VERSION ""

NS_ :

BS_:

BU_: PE3_ECU FR_Upright FL_Upright RR_Upright RL_Upright Data_MCU PWR_MCU Front_Sensor_Board Rear_Sensor_Board CG_Sensor_Board Telemetry Dash
VAL_TABLE_ Telem_OK_Value 1 "ERROR" 0 "OK" ;

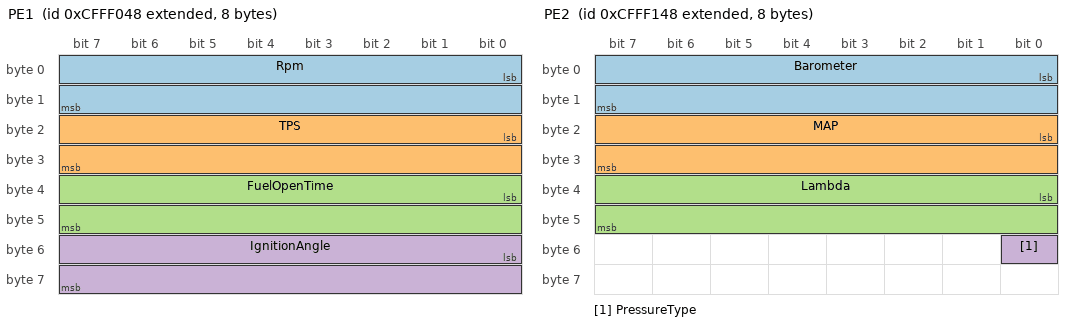
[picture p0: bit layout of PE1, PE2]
BO_ 2365583432 PE1: 8 PE3_ECU
 SG_ Rpm : 0|16@1+ (1,0) [0|30000] "rpm"  Telemetry
 SG_ TPS : 16|16@1- (0.1,0) [0|100] "%"  Telemetry
 SG_ FuelOpenTime : 32|16@1- (0.1,0) [0|30] "volts"  Telemetry
 SG_ IgnitionAngle : 48|16@1- (0.1,0) [-20|100] "deg"  Telemetry

BO_ 2365583688 PE2: 8 PE3_ECU
 SG_ Barometer : 0|16@1- (0.01,0) [0|300] "psi"  Telemetry
 SG_ MAP : 16|16@1- (0.01,0) [0|300] "psi"  Telemetry
 SG_ Lambda : 32|16@1- (0.01,0) [0|10] "lambda"  Telemetry
 SG_ PressureType : 48|1@1+ (1,0) [0|1] "0-psi,1-kPa"  Telemetry

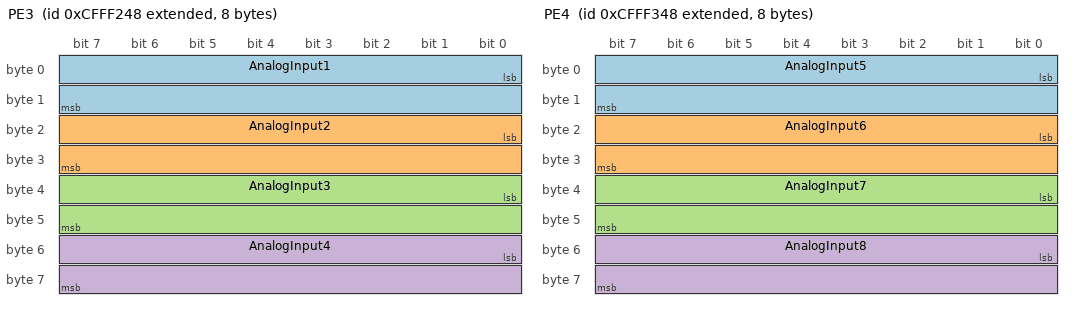
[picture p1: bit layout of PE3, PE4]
BO_ 2365583944 PE3: 8 PE3_ECU
 SG_ AnalogInput1 : 0|16@1- (0.001,0) [0|5] "volts"  Telemetry
 SG_ AnalogInput2 : 16|16@1- (0.001,0) [0|5] "volts"  Telemetry
 SG_ AnalogInput3 : 32|16@1- (0.001,0) [0|5] "volts"  Telemetry
 SG_ AnalogInput4 : 48|16@1- (0.001,0) [0|5] "volts"  Telemetry

BO_ 2365584200 PE4: 8 PE3_ECU
 SG_ AnalogInput5 : 0|16@1- (0.001,0) [0|5] "volts"  Telemetry
 SG_ AnalogInput6 : 16|16@1- (0.001,0) [0|5] "volts"  Telemetry
 SG_ AnalogInput7 : 32|16@1- (0.001,0) [0|5] "volts"  Telemetry
 SG_ AnalogInput8 : 48|16@1- (0.001,0) [0|5] "volts"  Telemetry

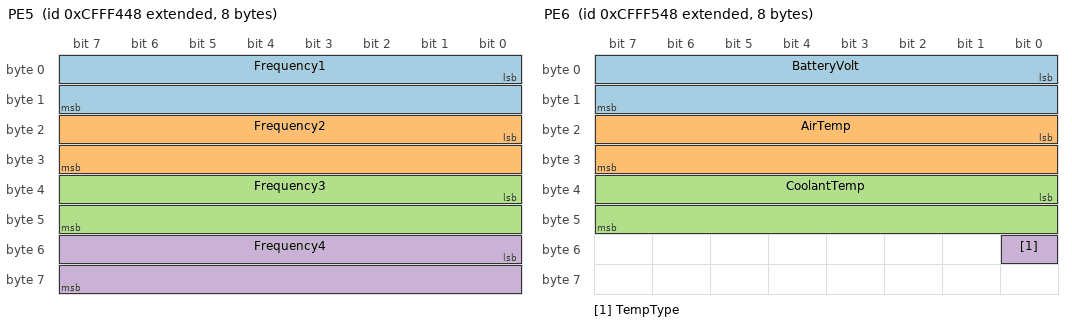
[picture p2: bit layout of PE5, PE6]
BO_ 2365584456 PE5: 8 PE3_ECU
 SG_ Frequency1 : 0|16@1- (0.001,0) [0|5] "volts"  Telemetry
 SG_ Frequency2 : 16|16@1- (0.001,0) [0|5] "volts"  Telemetry
 SG_ Frequency3 : 32|16@1- (0.001,0) [0|5] "volts"  Telemetry
 SG_ Frequency4 : 48|16@1- (0.001,0) [0|5] "volts"  Telemetry

BO_ 2365584712 PE6: 8 PE3_ECU
 SG_ BatteryVolt : 0|16@1- (0.01,0) [0|22] "volts"  Telemetry
 SG_ AirTemp : 16|16@1- (0.1,0) [-1000|1000] "F"  Telemetry
 SG_ CoolantTemp : 32|16@1- (0.1,0) [-1000|1000] "F"  Telemetry
 SG_ TempType : 48|1@1+ (1,0) [0|1] "0-F,1-C"  Telemetry

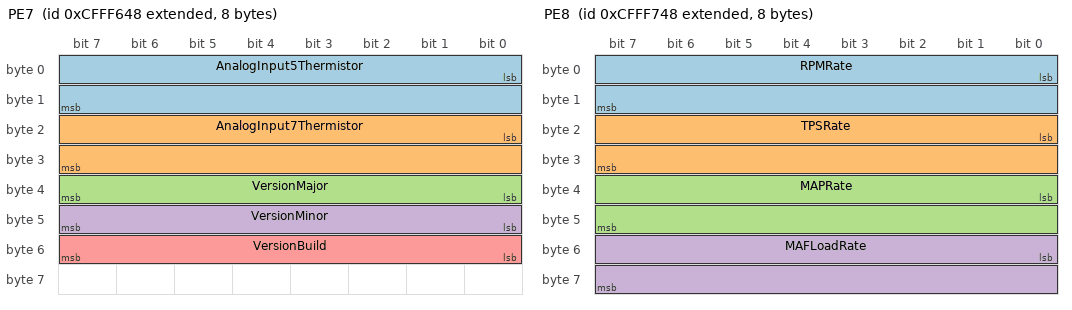
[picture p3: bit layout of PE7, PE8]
BO_ 2365584968 PE7: 8 PE3_ECU
 SG_ AnalogInput5Thermistor : 0|16@1- (0.1,0) [-1000|1000] "F"  Telemetry
 SG_ AnalogInput7Thermistor : 16|16@1- (0.1,0) [-1000|1000] "F"  Telemetry
 SG_ VersionMajor : 32|8@1+ (1,0) [0|255] ""  Telemetry
 SG_ VersionMinor : 40|8@1+ (1,0) [0|255] ""  Telemetry
 SG_ VersionBuild : 48|8@1+ (1,0) [0|255] ""  Telemetry

BO_ 2365585224 PE8: 8 PE3_ECU
 SG_ RPMRate : 0|16@1- (1,0) [-10000|10000] "rpm/sec"  Telemetry
 SG_ TPSRate : 16|16@1- (1,0) [-3000|3000] "%/sec"  Telemetry
 SG_ MAPRate : 32|16@1- (1,0) [-3000|3000] "psi/sec"  Telemetry
 SG_ MAFLoadRate : 48|16@1- (0.1,0) [-300|300] "g/rev/sec"  Telemetry

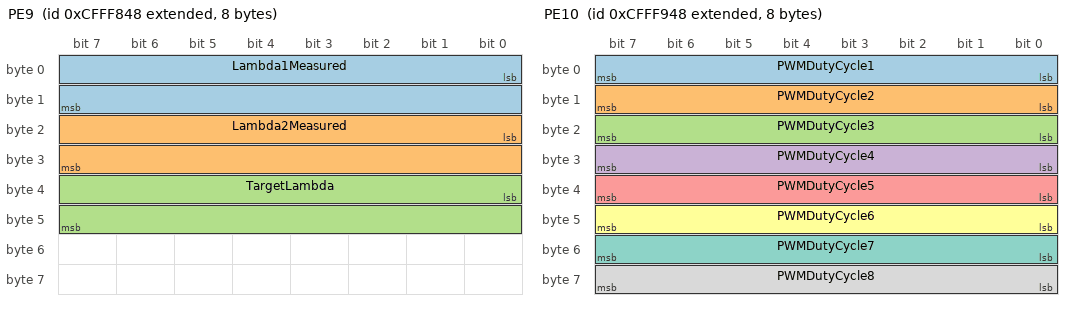
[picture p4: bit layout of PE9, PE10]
BO_ 2365585480 PE9: 8 PE3_ECU
 SG_ Lambda1Measured : 0|16@1- (0.01,0) [0|10] "lambda"  Telemetry
 SG_ Lambda2Measured : 16|16@1- (0.01,0) [0|10] "lambda"  Telemetry
 SG_ TargetLambda : 32|16@1- (0.01,0) [0|2.5] "lambda"  Telemetry

BO_ 2365585736 PE10: 8 PE3_ECU
 SG_ PWMDutyCycle1 : 0|8@1+ (0.5,0) [0|100] "%"  Telemetry
 SG_ PWMDutyCycle2 : 8|8@1+ (0.5,0) [0|100] "%"  Telemetry
 SG_ PWMDutyCycle3 : 16|8@1+ (0.5,0) [0|100] "%"  Telemetry
 SG_ PWMDutyCycle4 : 24|8@1+ (0.5,0) [0|100] "%"  Telemetry
 SG_ PWMDutyCycle5 : 32|8@1+ (0.5,0) [0|100] "%"  Telemetry
 SG_ PWMDutyCycle6 : 40|8@1+ (0.5,0) [0|100] "%"  Telemetry
 SG_ PWMDutyCycle7 : 48|8@1+ (0.5,0) [0|100] "%"  Telemetry
 SG_ PWMDutyCycle8 : 56|8@1+ (0.5,0) [0|100] "%"  Telemetry

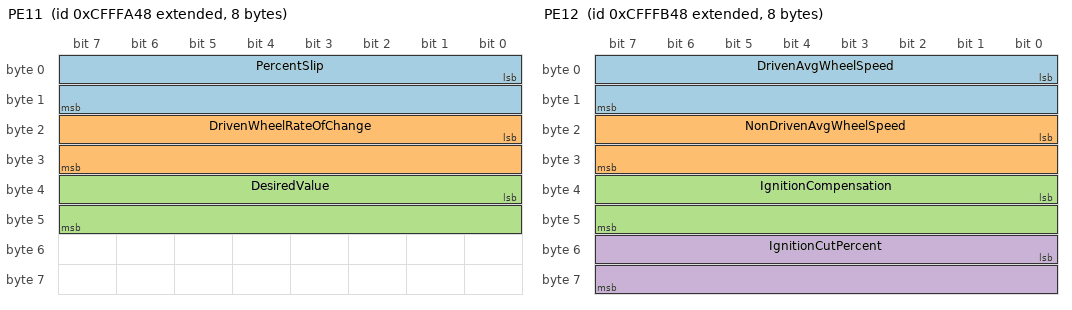
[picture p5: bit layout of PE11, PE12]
BO_ 2365585992 PE11: 8 PE3_ECU
 SG_ PercentSlip : 0|16@1- (0.1,0) [-3000|3000] "%"  Telemetry
 SG_ DrivenWheelRateOfChange : 16|16@1- (0.1,0) [-3000|3000] "fs/sec/sec"  Telemetry
 SG_ DesiredValue : 32|16@1- (0.1,0) [-3000|3000] "%"  Telemetry

BO_ 2365586248 PE12: 8 PE3_ECU
 SG_ DrivenAvgWheelSpeed : 0|16@1+ (0.1,0) [0|3000] "ft/sec"  Telemetry
 SG_ NonDrivenAvgWheelSpeed : 16|16@1+ (0.1,0) [0|3000] "ft/sec"  Telemetry
 SG_ IgnitionCompensation : 32|16@1- (0.1,0) [0|100] "deg"  Telemetry
 SG_ IgnitionCutPercent : 48|16@1- (0.1,0) [0|100] "%"  Telemetry

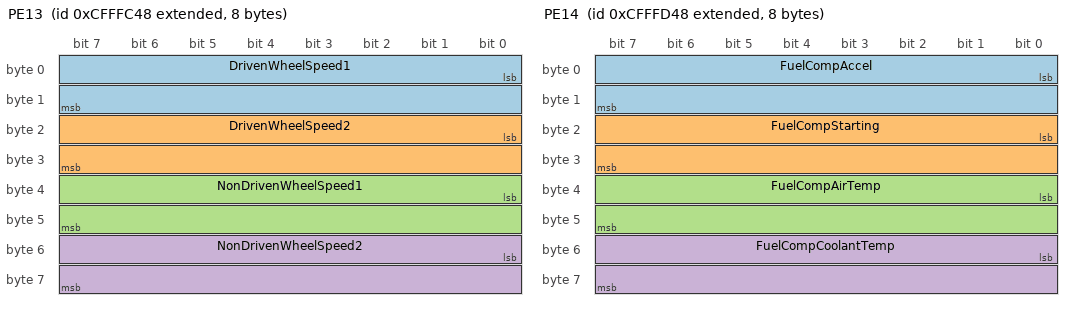
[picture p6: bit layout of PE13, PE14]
BO_ 2365586504 PE13: 8 PE3_ECU
 SG_ DrivenWheelSpeed1 : 0|16@1+ (0.1,0) [0|3000] "ft/sec"  Telemetry
 SG_ DrivenWheelSpeed2 : 16|16@1+ (0.1,0) [0|3000] "ft/sec"  Telemetry
 SG_ NonDrivenWheelSpeed1 : 32|16@1+ (0.1,0) [0|3000] "ft/sec"  Telemetry
 SG_ NonDrivenWheelSpeed2 : 48|16@1+ (0.1,0) [0|3000] "ft/sec"  Telemetry

BO_ 2365586760 PE14: 8 PE3_ECU
 SG_ FuelCompAccel : 0|16@1- (0.1,0) [0|500] "%"  Telemetry
 SG_ FuelCompStarting : 16|16@1- (0.1,0) [0|500] "%"  Telemetry
 SG_ FuelCompAirTemp : 32|16@1- (0.1,0) [0|500] "%"  Telemetry
 SG_ FuelCompCoolantTemp : 48|16@1- (0.1,0) [0|500] "%"  Telemetry

BO_ 2365587016 PE15: 8 PE3_ECU
 SG_ FuelCompBarometer : 0|16@1- (0.1,0) [0|500] "%"  Telemetry
 SG_ FuelCompMAP : 16|16@1- (0.1,0) [0|500] "%"  Telemetry

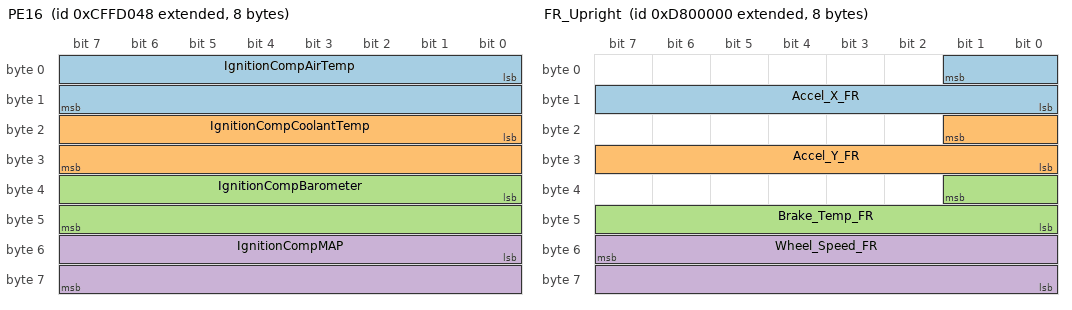
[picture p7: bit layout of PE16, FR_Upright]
BO_ 2365575240 PE16: 8 PE3_ECU
 SG_ IgnitionCompAirTemp : 0|16@1- (0.1,0) [-20|20] "deg"  Telemetry
 SG_ IgnitionCompCoolantTemp : 16|16@1- (0.1,0) [-20|20] "deg"  Telemetry
 SG_ IgnitionCompBarometer : 32|16@1- (0.1,0) [-20|20] "deg"  Telemetry
 SG_ IgnitionCompMAP : 48|16@1- (0.1,0) [-20|20] "deg"  Telemetry

BO_ 2373976064 FR_Upright: 8 FR_Upright
 SG_ Accel_X_FR : 1|10@0+ (1,0) [0|0] ""  Telemetry
 SG_ Accel_Y_FR : 17|10@0+ (1,0) [0|0] ""  Telemetry
 SG_ Brake_Temp_FR : 33|10@0+ (1,0) [0|0] ""  Telemetry
 SG_ Wheel_Speed_FR : 55|16@0+ (1,0) [0|0] ""  Telemetry

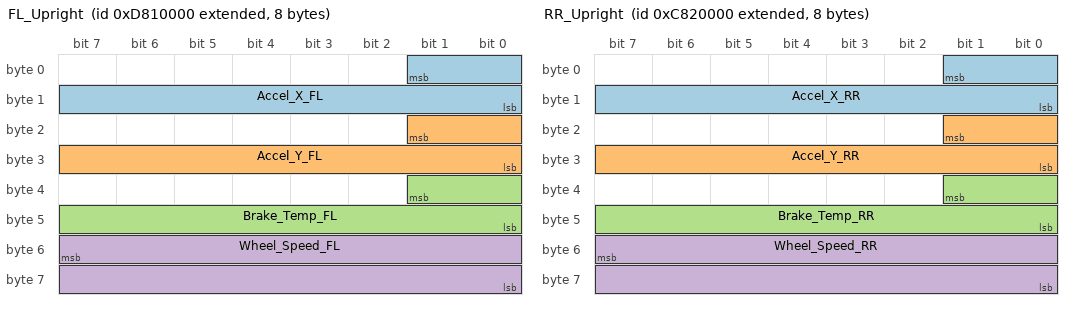
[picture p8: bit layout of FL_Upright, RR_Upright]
BO_ 2374041600 FL_Upright: 8 FL_Upright
 SG_ Accel_X_FL : 1|10@0+ (1,0) [0|0] ""  Telemetry
 SG_ Accel_Y_FL : 17|10@0+ (1,0) [0|0] ""  Telemetry
 SG_ Brake_Temp_FL : 33|10@0+ (1,0) [0|0] ""  Telemetry
 SG_ Wheel_Speed_FL : 55|16@0+ (1,0) [0|0] ""  Telemetry

BO_ 2357329920 RR_Upright: 8 RR_Upright
 SG_ Accel_X_RR : 1|10@0+ (1,0) [0|0] ""  Telemetry
 SG_ Accel_Y_RR : 17|10@0+ (1,0) [0|0] ""  Telemetry
 SG_ Brake_Temp_RR : 33|10@0+ (1,0) [0|0] ""  Telemetry
 SG_ Wheel_Speed_RR : 55|16@0+ (1,0) [0|0] ""  Telemetry

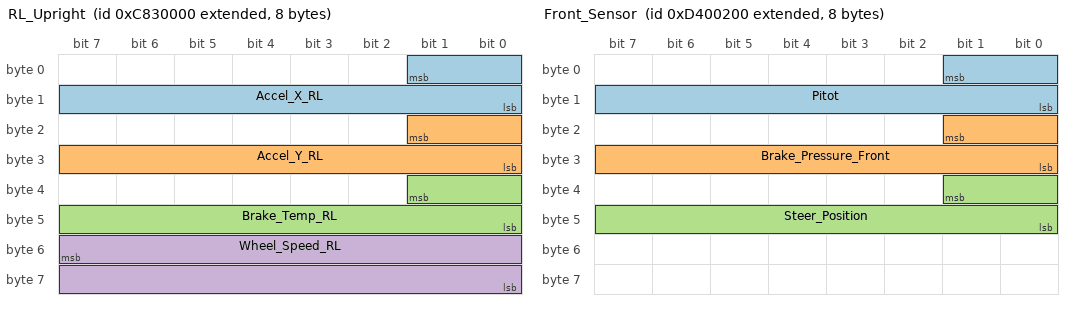
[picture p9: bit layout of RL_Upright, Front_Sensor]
BO_ 2357395456 RL_Upright: 8 RL_Upright
 SG_ Accel_X_RL : 1|10@0+ (1,0) [0|0] ""  Telemetry
 SG_ Accel_Y_RL : 17|10@0+ (1,0) [0|0] ""  Telemetry
 SG_ Brake_Temp_RL : 33|10@0+ (1,0) [0|0] ""  Telemetry
 SG_ Wheel_Speed_RL : 55|16@0+ (1,0) [0|0] ""  Telemetry

BO_ 2369782272 Front_Sensor: 8 Front_Sensor_Board
 SG_ Pitot : 1|10@0+ (1,0) [0|0] ""  Telemetry
 SG_ Brake_Pressure_Front : 17|10@0+ (1,0) [0|0] ""  Telemetry
 SG_ Steer_Position : 33|10@0+ (1,0) [0|0] ""  Telemetry

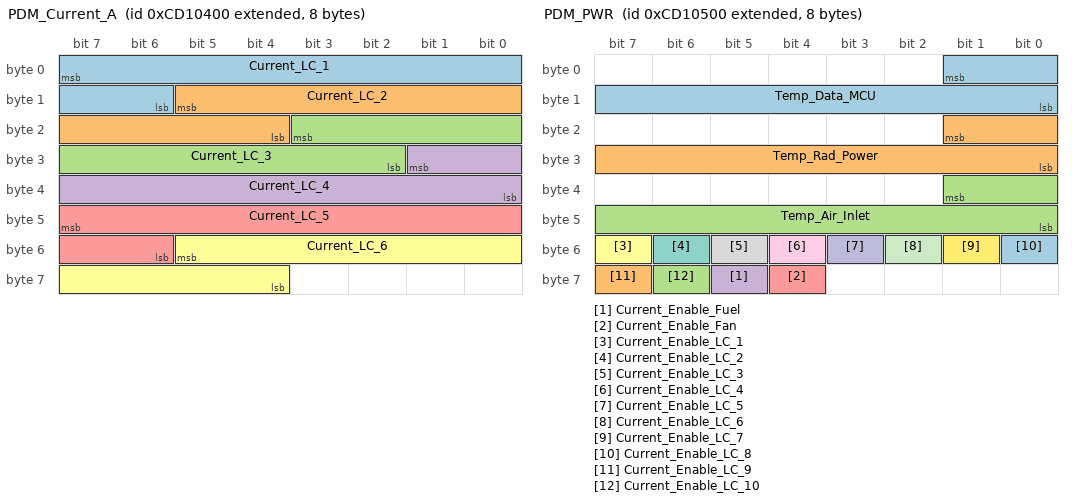
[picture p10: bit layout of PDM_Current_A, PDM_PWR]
BO_ 2362508288 PDM_Current_A: 8 PWR_MCU
 SG_ Current_LC_1 : 7|10@0+ (1,0) [0|0] ""  Telemetry
 SG_ Current_LC_2 : 13|10@0+ (1,0) [0|0] ""  Telemetry
 SG_ Current_LC_3 : 19|10@0+ (1,0) [0|0] ""  Telemetry
 SG_ Current_LC_4 : 25|10@0+ (1,0) [0|0] ""  Telemetry
 SG_ Current_LC_5 : 47|10@0+ (1,0) [0|0] ""  Telemetry
 SG_ Current_LC_6 : 53|10@0+ (1,0) [0|0] ""  Telemetry

BO_ 2362508544 PDM_PWR: 8 PWR_MCU
 SG_ Temp_Data_MCU : 1|10@0+ (1,0) [0|0] ""  Telemetry
 SG_ Temp_Rad_Power : 17|10@0+ (1,0) [0|0] ""  Telemetry
 SG_ Temp_Air_Inlet : 33|10@0+ (1,0) [0|0] ""  Telemetry
 SG_ Current_Enable_Fuel : 61|1@0+ (1,0) [0|0] ""  Telemetry
 SG_ Current_Enable_Fan : 60|1@0+ (1,0) [0|0] ""  Telemetry
 SG_ Current_Enable_LC_1 : 55|1@0+ (1,0) [0|0] ""  Telemetry
 SG_ Current_Enable_LC_2 : 54|1@0+ (1,0) [0|0] ""  Telemetry
 SG_ Current_Enable_LC_3 : 53|1@0+ (1,0) [0|0] ""  Telemetry
 SG_ Current_Enable_LC_4 : 52|1@0+ (1,0) [0|0] ""  Telemetry
 SG_ Current_Enable_LC_5 : 51|1@0+ (1,0) [0|0] ""  Telemetry
 SG_ Current_Enable_LC_6 : 50|1@0+ (1,0) [0|0] ""  Telemetry
 SG_ Current_Enable_LC_7 : 49|1@0+ (1,0) [0|0] ""  Telemetry
 SG_ Current_Enable_LC_8 : 48|1@0+ (1,0) [0|0] ""  Telemetry
 SG_ Current_Enable_LC_9 : 63|1@0+ (1,0) [0|0] ""  Telemetry
 SG_ Current_Enable_LC_10 : 62|1@0+ (1,0) [0|0] ""  Telemetry

BO_ 2376074752 GPS_POS: 8 Telemetry
 SG_ GPS_Lat : 7|32@0- (1E-006,0) [-90|90] "deg" Vector__XXX
 SG_ GPS_Long : 39|32@0- (1E-006,0) [-180|180] "deg" Vector__XXX

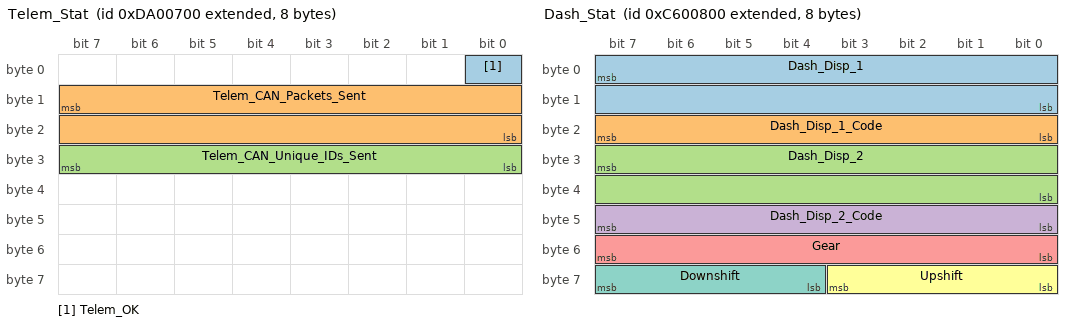
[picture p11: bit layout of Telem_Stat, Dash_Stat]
BO_ 2376075008 Telem_Stat: 8 Telemetry
 SG_ Telem_OK : 0|1@0+ (1,0) [0|0] "" Vector__XXX
 SG_ Telem_CAN_Packets_Sent : 15|16@0+ (1,0) [0|0] "" Vector__XXX
 SG_ Telem_CAN_Unique_IDs_Sent : 31|8@0+ (1,0) [0|0] "" Vector__XXX

BO_ 2355103744 Dash_Stat: 8 Dash
 SG_ Dash_Disp_1 : 7|16@0+ (1,0) [0|0] ""  Telemetry
 SG_ Dash_Disp_1_Code : 23|8@0+ (1,0) [0|0] ""  Telemetry
 SG_ Dash_Disp_2 : 31|16@0+ (1,0) [0|0] ""  Telemetry
 SG_ Dash_Disp_2_Code : 47|8@0+ (1,0) [0|0] ""  Telemetry
 SG_ Gear : 55|8@0+ (1,0) [0|0] ""  Telemetry
 SG_ Upshift : 59|4@0+ (1,0) [0|0] ""  Telemetry
 SG_ Downshift : 63|4@0+ (1,0) [0|0] ""  Telemetry

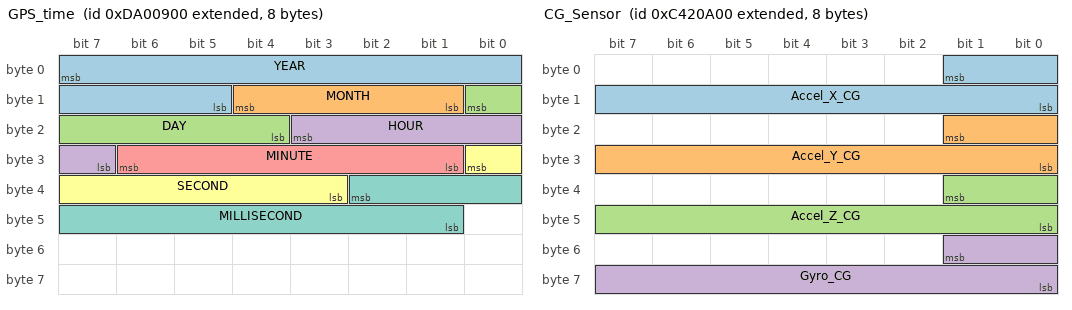
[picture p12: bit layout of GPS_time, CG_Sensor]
BO_ 2376075520 GPS_time: 8 Telemetry
 SG_ YEAR : 7|11@0+ (1,2000) [0|0] "" Vector__XXX
 SG_ MONTH : 12|4@0+ (1,0) [0|0] "" Vector__XXX
 SG_ DAY : 8|5@0+ (1,0) [0|0] "" Vector__XXX
 SG_ HOUR : 19|5@0+ (1,0) [0|0] "" Vector__XXX
 SG_ MINUTE : 30|6@0+ (1,0) [0|0] "" Vector__XXX
 SG_ SECOND : 24|6@0+ (1,0) [0|0] "" Vector__XXX
 SG_ MILLISECOND : 34|10@0+ (1,0) [0|0] "" Vector__XXX

BO_ 2353138176 CG_Sensor: 8 CG_Sensor_Board
 SG_ Accel_X_CG : 1|10@0+ (1,0) [0|0] ""  Telemetry
 SG_ Accel_Y_CG : 17|10@0+ (1,0) [0|0] ""  Telemetry
 SG_ Accel_Z_CG : 33|10@0+ (1,0) [0|0] ""  Telemetry
 SG_ Gyro_CG : 49|10@0+ (1,0) [0|0] ""  Telemetry

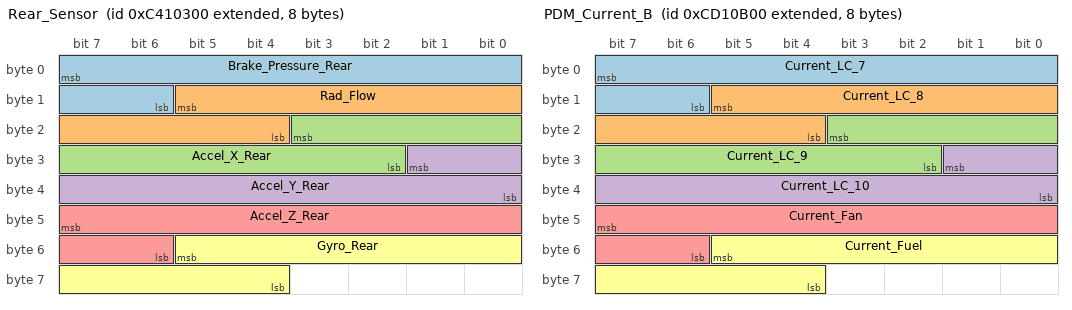
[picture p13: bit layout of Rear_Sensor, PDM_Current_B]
BO_ 2353070848 Rear_Sensor: 8 Rear_Sensor_Board
 SG_ Brake_Pressure_Rear : 7|10@0+ (1,0) [0|0] ""  Telemetry
 SG_ Rad_Flow : 13|10@0+ (1,0) [0|0] ""  Telemetry
 SG_ Accel_X_Rear : 19|10@0+ (1,0) [0|0] ""  Telemetry
 SG_ Accel_Y_Rear : 25|10@0+ (1,0) [0|0] ""  Telemetry
 SG_ Accel_Z_Rear : 47|10@0+ (1,0) [0|0] ""  Telemetry
 SG_ Gyro_Rear : 53|10@0+ (1,0) [0|0] ""  Telemetry

BO_ 2362510080 PDM_Current_B: 8 PWR_MCU
 SG_ Current_LC_7 : 7|10@0+ (1,0) [0|0] ""  Telemetry
 SG_ Current_LC_8 : 13|10@0+ (1,0) [0|0] ""  Telemetry
 SG_ Current_LC_9 : 19|10@0+ (1,0) [0|0] ""  Telemetry
 SG_ Current_LC_10 : 25|10@0+ (1,0) [0|0] ""  Telemetry
 SG_ Current_Fan : 47|10@0+ (1,0) [0|0] ""  Telemetry
 SG_ Current_Fuel : 53|10@0+ (1,0) [0|0] ""  Telemetry

BA_DEF_ BO_  "GenMsgSendType" ENUM  "Cyclic";
BA_DEF_ BO_  "GenMsgCycleTime" INT 1 10000;
BA_DEF_DEF_  "GenMsgSendType" "Cyclic";
BA_DEF_DEF_  "GenMsgCycleTime" 100;
BA_ "GenMsgCycleTime" BO_ 2365583432 50;
BA_ "GenMsgCycleTime" BO_ 2365583688 50;
BA_ "GenMsgCycleTime" BO_ 2365584712 1000;
BA_ "GenMsgCycleTime" BO_ 2365584968 1000;
BA_ "GenMsgCycleTime" BO_ 2373976064 4;
BA_ "GenMsgCycleTime" BO_ 2374041600 4;
BA_ "GenMsgCycleTime" BO_ 2357329920 4;
BA_ "GenMsgCycleTime" BO_ 2357395456 4;
BA_ "GenMsgCycleTime" BO_ 2369782272 4;
BA_ "GenMsgCycleTime" BO_ 2376074752 1000;
BA_ "GenMsgCycleTime" BO_ 2376075008 1000;
BA_ "GenMsgCycleTime" BO_ 2376075520 1000;
BA_ "GenMsgCycleTime" BO_ 2353138176 4;
BA_ "GenMsgCycleTime" BO_ 2353070848 4;
VAL_ 2376075008 Telem_OK 1 "ERROR" 0 "OK" ;
